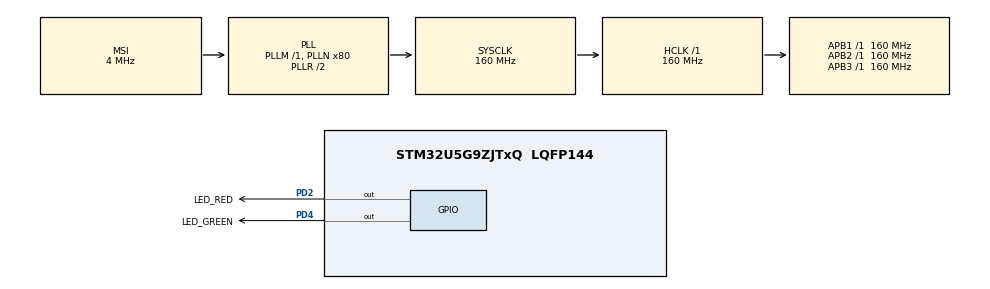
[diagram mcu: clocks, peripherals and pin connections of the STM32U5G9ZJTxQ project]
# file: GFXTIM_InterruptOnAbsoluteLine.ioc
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CORTEX_M33_NS.userName=CORTEX_M33
GFXTIM.AbsoluteTimerActivation=ENABLE
GFXTIM.EventGenerator2=DISABLE
GFXTIM.FrameClockSrc=GFXTIM_FRAME_CLK_SRC_FCC_UNDERFLOW
GFXTIM.LCCReloadValue=159999
GFXTIM.LineClockCounter=ENABLE
GFXTIM.LineCompare1Interrupt=ENABLE
GFXTIM.LineCompare1Value=1500
GFXTIM.LineCompare2Interrupt=ENABLE
GFXTIM.LineCompare2Value=3000
GFXTIM.TearingEffectActivation=DISABLE
Mcu.Family=STM32U5
Mcu.Name=STM32U5G9ZJTxQ
Mcu.Package=LQFP144
NVIC.GFXTIM_IRQn=true\:0\:0\:false\:false\:true\:true\:true\:true
NVIC.PriorityGroup=NVIC_PRIORITYGROUP_4
PD2.GPIO_Label=LED_RED
PD2.PinState=GPIO_PIN_SET
PD2.Signal=GPIO_Output
PD4.GPIO_Label=LED_GREEN
PD4.PinState=GPIO_PIN_SET
PD4.Signal=GPIO_Output
PWR.PowerMode=PWR_SMPS_SUPPLY
ProjectManager.HeapSize=0x200
ProjectManager.StackSize=0x400
ProjectManager.TargetToolchain=EWARM V8.50
RCC.ADCFreq_Value=16000000
RCC.AHBFreq_Value=160000000
RCC.APB1Freq_Value=160000000
RCC.APB1TimFreq_Value=160000000
RCC.APB2Freq_Value=160000000
RCC.APB2TimFreq_Value=160000000
RCC.APB3Freq_Value=160000000
RCC.CortexFreq_Value=160000000
RCC.EPOD_VALUE=4000000
RCC.HCLKFreq_Value=160000000
RCC.HSE_VALUE=16000000
RCC.HSI48_VALUE=48000000
RCC.HSI_VALUE=16000000
RCC.LSE_VALUE=32768
RCC.LSIDIV_VALUE=32000
RCC.MSI_VALUE=4000000
RCC.PLL2FRACN=0
RCC.PLL3FRACN=0
RCC.PLLFRACN=0
RCC.PLLN=80
RCC.SYSCLKFreq_VALUE=160000000
RCC.SYSCLKSource=RCC_SYSCLKSOURCE_PLLCLK
RCC.VCOOutputFreq_Value=320000000
VP_GFXTIM_VS_GFXTIM.Mode=GFXTIM_Activate
VP_ICACHE_VS_ICACHE.Mode=DirectMappedCache
VP_PWR_VS_DBSignals.Mode=DisableDeadBatterySignals
VP_PWR_VS_LPOM.Mode=PowerOptimisation
VP_PWR_VS_SECSignals.Mode=Security/Privilege
board=custom

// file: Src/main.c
/* USER CODE BEGIN Header */
/**
  ******************************************************************************
  * @file           : main.c
  * @brief          : Main program body
  ******************************************************************************
  * @attention
  *
  * Copyright (c) 2023 STMicroelectronics.
  * All rights reserved.
  *
  * This software is licensed under terms that can be found in the LICENSE file
  * in the root directory of this software component.
  * If no LICENSE file comes with this software, it is provided AS-IS.
  *
  ******************************************************************************
  */
/* USER CODE END Header */
#include "main.h"

/* USER CODE BEGIN Includes */
#include "stm32u5g9j_discovery.h"
/* USER CODE END Includes */

GFXTIM_HandleTypeDef hgfxtim;

/* USER CODE BEGIN PV */
__IO uint32_t Time1Result = 0;
__IO uint32_t Time2Result = 0;
uint32_t tickstart;
static __IO uint32_t CL1Tick = 0;
static __IO uint32_t CL2Tick = 0;
/* USER CODE END PV */

void SystemClock_Config(void);
static void SystemPower_Config(void);
static void MX_GPIO_Init(void);
static void MX_GFXTIM_Init(void);
static void MX_ICACHE_Init(void);

int main(void)
{

  /* MCU Configuration--------------------------------------------------------*/

  /* Reset of all peripherals, Initializes the Flash interface and the Systick. */
  HAL_Init();

  /* Configure the System Power */
  SystemPower_Config();

  /* Configure the system clock */
  SystemClock_Config();

  /* Initialize all configured peripherals */
  MX_GPIO_Init();
  MX_GFXTIM_Init();
  MX_ICACHE_Init();
  /* USER CODE BEGIN 2 */
  HAL_GFXTIM_AbsoluteTimer_Start(&hgfxtim);
  tickstart = HAL_GetTick();
  while (((HAL_GetTick() - tickstart) < 1520) && (CL1Tick == 0))
  {
  }
  if (CL1Tick - tickstart == 1500)
  {
    Time1Result = 1;
  }

  while (((HAL_GetTick() - tickstart) < 3020) && (CL2Tick == 0))
  {
  }
  if (CL2Tick - tickstart == 3000)
  {
    Time2Result = 1;
  }

  HAL_GFXTIM_AbsoluteTimer_Stop(&hgfxtim);

  if ((Time1Result != 0) && (Time2Result != 0))
  {
    HAL_GPIO_WritePin(LED_GREEN_GPIO_Port, LED_GREEN_Pin, GPIO_PIN_RESET);
  }
  else
  {
    HAL_GPIO_WritePin(LED_RED_GPIO_Port, LED_RED_Pin, GPIO_PIN_RESET);
  }
  /* USER CODE END 2 */

  /* Infinite loop */
  while (1)
  {

  }
}

void SystemClock_Config(void)
{
  RCC_OscInitTypeDef RCC_OscInitStruct = {0};
  RCC_ClkInitTypeDef RCC_ClkInitStruct = {0};

  /** Configure the main internal regulator output voltage
  */
  if (HAL_PWREx_ControlVoltageScaling(PWR_REGULATOR_VOLTAGE_SCALE1) != HAL_OK)
  {
    Error_Handler();
  }

  /** Initializes the CPU, AHB and APB buses clocks
  */
  RCC_OscInitStruct.OscillatorType = RCC_OSCILLATORTYPE_MSI;
  RCC_OscInitStruct.MSIState = RCC_MSI_ON;
  RCC_OscInitStruct.MSICalibrationValue = RCC_MSICALIBRATION_DEFAULT;
  RCC_OscInitStruct.MSIClockRange = RCC_MSIRANGE_4;
  RCC_OscInitStruct.PLL.PLLState = RCC_PLL_ON;
  RCC_OscInitStruct.PLL.PLLSource = RCC_PLLSOURCE_MSI;
  RCC_OscInitStruct.PLL.PLLMBOOST = RCC_PLLMBOOST_DIV1;
  RCC_OscInitStruct.PLL.PLLM = 1;
  RCC_OscInitStruct.PLL.PLLN = 80;
  RCC_OscInitStruct.PLL.PLLP = 2;
  RCC_OscInitStruct.PLL.PLLQ = 2;
  RCC_OscInitStruct.PLL.PLLR = 2;
  RCC_OscInitStruct.PLL.PLLRGE = RCC_PLLVCIRANGE_0;
  RCC_OscInitStruct.PLL.PLLFRACN = 0;
  if (HAL_RCC_OscConfig(&RCC_OscInitStruct) != HAL_OK)
  {
    Error_Handler();
  }

  /** Initializes the CPU, AHB and APB buses clocks
  */
  RCC_ClkInitStruct.ClockType = RCC_CLOCKTYPE_HCLK|RCC_CLOCKTYPE_SYSCLK
                              |RCC_CLOCKTYPE_PCLK1|RCC_CLOCKTYPE_PCLK2
                              |RCC_CLOCKTYPE_PCLK3;
  RCC_ClkInitStruct.SYSCLKSource = RCC_SYSCLKSOURCE_PLLCLK;
  RCC_ClkInitStruct.AHBCLKDivider = RCC_SYSCLK_DIV1;
  RCC_ClkInitStruct.APB1CLKDivider = RCC_HCLK_DIV1;
  RCC_ClkInitStruct.APB2CLKDivider = RCC_HCLK_DIV1;
  RCC_ClkInitStruct.APB3CLKDivider = RCC_HCLK_DIV1;

  if (HAL_RCC_ClockConfig(&RCC_ClkInitStruct, FLASH_LATENCY_4) != HAL_OK)
  {
    Error_Handler();
  }
}

/**
  * @brief Power Configuration
  * @retval None
  */
static void SystemPower_Config(void)
{

  /*
   * Disable the internal Pull-Up in Dead Battery pins of UCPD peripheral
   */
  HAL_PWREx_DisableUCPDDeadBattery();

  /*
   * Switch to SMPS regulator instead of LDO
   */
  if (HAL_PWREx_ConfigSupply(PWR_SMPS_SUPPLY) != HAL_OK)
  {
    Error_Handler();
  }
}

static void MX_GFXTIM_Init(void)
{

  GFXTIM_ClockGeneratorConfigTypeDef pClockGeneratorConfig = {0};
  GFXTIM_AbsoluteTimerConfigTypeDef pAbsoluteTimerConfig = {0};

  hgfxtim.Instance = GFXTIM;
  hgfxtim.Init.SynchroSrc = GFXTIM_SYNC_SRC_HSYNC_VSYNC_0;
  if (HAL_GFXTIM_Init(&hgfxtim) != HAL_OK)
  {
    Error_Handler();
  }
  pClockGeneratorConfig.LCCHwReloadSrc = GFXTIM_LCC_HW_RELOAD_SRC_NONE;
  pClockGeneratorConfig.LCCReloadValue = 159999;
  pClockGeneratorConfig.LCCClockSrc = GFXTIM_LCC_CLK_SRC_SYSCLOCK;
  pClockGeneratorConfig.LineClockSrc = GFXTIM_LINE_CLK_SRC_LCC_UNDERFLOW;
  pClockGeneratorConfig.FrameClockSrc = GFXTIM_FRAME_CLK_SRC_FCC_UNDERFLOW;
  pClockGeneratorConfig.LineClockCalib = GFXTIM_LINE_CLK_CALIB_DISABLE;
  pClockGeneratorConfig.FrameClockCalib = GFXTIM_FRAME_CLK_CALIB_DISABLE;
  if (HAL_GFXTIM_ClockGenerator_Config(&hgfxtim, &pClockGeneratorConfig) != HAL_OK)
  {
    Error_Handler();
  }
  pAbsoluteTimerConfig.FrameCompare1Value = 0;
  pAbsoluteTimerConfig.LineCompare1Value = 1500;
  pAbsoluteTimerConfig.LineCompare2Value = 3000;
  pAbsoluteTimerConfig.FrameCounterValue = 0;
  pAbsoluteTimerConfig.LineCounterValue = 0;
  pAbsoluteTimerConfig.FrameOverflowInterrupt = DISABLE;
  pAbsoluteTimerConfig.FrameCompare1Interrupt = DISABLE;
  pAbsoluteTimerConfig.LineOverflowInterrupt = DISABLE;
  pAbsoluteTimerConfig.LineCompare1Interrupt = ENABLE;
  pAbsoluteTimerConfig.LineCompare2Interrupt = ENABLE;
  if (HAL_GFXTIM_AbsoluteTimer_Config(&hgfxtim, &pAbsoluteTimerConfig) != HAL_OK)
  {
    Error_Handler();
  }

}

static void MX_ICACHE_Init(void)
{

  /** Enable instruction cache in 1-way (direct mapped cache)
  */
  if (HAL_ICACHE_ConfigAssociativityMode(ICACHE_1WAY) != HAL_OK)
  {
    Error_Handler();
  }
  if (HAL_ICACHE_Enable() != HAL_OK)
  {
    Error_Handler();
  }

}

static void MX_GPIO_Init(void)
{
  GPIO_InitTypeDef GPIO_InitStruct = {0};

  /* GPIO Ports Clock Enable */
  __HAL_RCC_GPIOD_CLK_ENABLE();

  /*Configure GPIO pin Output Level */
  HAL_GPIO_WritePin(GPIOD, LED_RED_Pin|LED_GREEN_Pin, GPIO_PIN_SET);

  /*Configure GPIO pins : LED_RED_Pin LED_GREEN_Pin */
  GPIO_InitStruct.Pin = LED_RED_Pin|LED_GREEN_Pin;
  GPIO_InitStruct.Mode = GPIO_MODE_OUTPUT_PP;
  GPIO_InitStruct.Pull = GPIO_NOPULL;
  GPIO_InitStruct.Speed = GPIO_SPEED_FREQ_LOW;
  HAL_GPIO_Init(GPIOD, &GPIO_InitStruct);

}

/* USER CODE BEGIN 4 */
void HAL_GFXTIM_AbsoluteTimer_ALCC1Callback(GFXTIM_HandleTypeDef *hgfxtim)
{
  CL1Tick = HAL_GetTick();
}

void HAL_GFXTIM_AbsoluteTimer_ALCC2Callback(GFXTIM_HandleTypeDef *hgfxtim)
{
  CL2Tick = HAL_GetTick();
}
/* USER CODE END 4 */

void Error_Handler(void)
{
  /* USER CODE BEGIN Error_Handler_Debug */
  /* User can add his own implementation to report the HAL error return state */
  __disable_irq();
  HAL_GPIO_WritePin(GPIOD, LED_RED_Pin, GPIO_PIN_RESET);
  while (1)
  {

  }
  /* USER CODE END Error_Handler_Debug */
}
